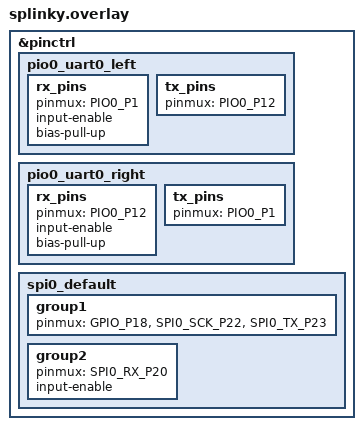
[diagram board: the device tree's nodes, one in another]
&pinctrl {
    pio0_uart0_left: pio0_uart0_left {
        rx_pins {
            pinmux = <PIO0_P1>;
            input-enable;
            bias-pull-up;
        };
        tx_pins {
            pinmux = <PIO0_P12>;
        };
    };
    pio0_uart0_right: pio0_uart0_right {
        rx_pins {
            pinmux = <PIO0_P12>;
            input-enable;
            bias-pull-up;
        };
        tx_pins {
            pinmux = <PIO0_P1>;
        };
    };

    spi0_default: spi0_default {
        group1 {
            pinmux = <GPIO_P18>, <SPI0_SCK_P22>, <SPI0_TX_P23>;
        };
        group2 {
            pinmux = <SPI0_RX_P20>;
            input-enable;
        };
    };
};
